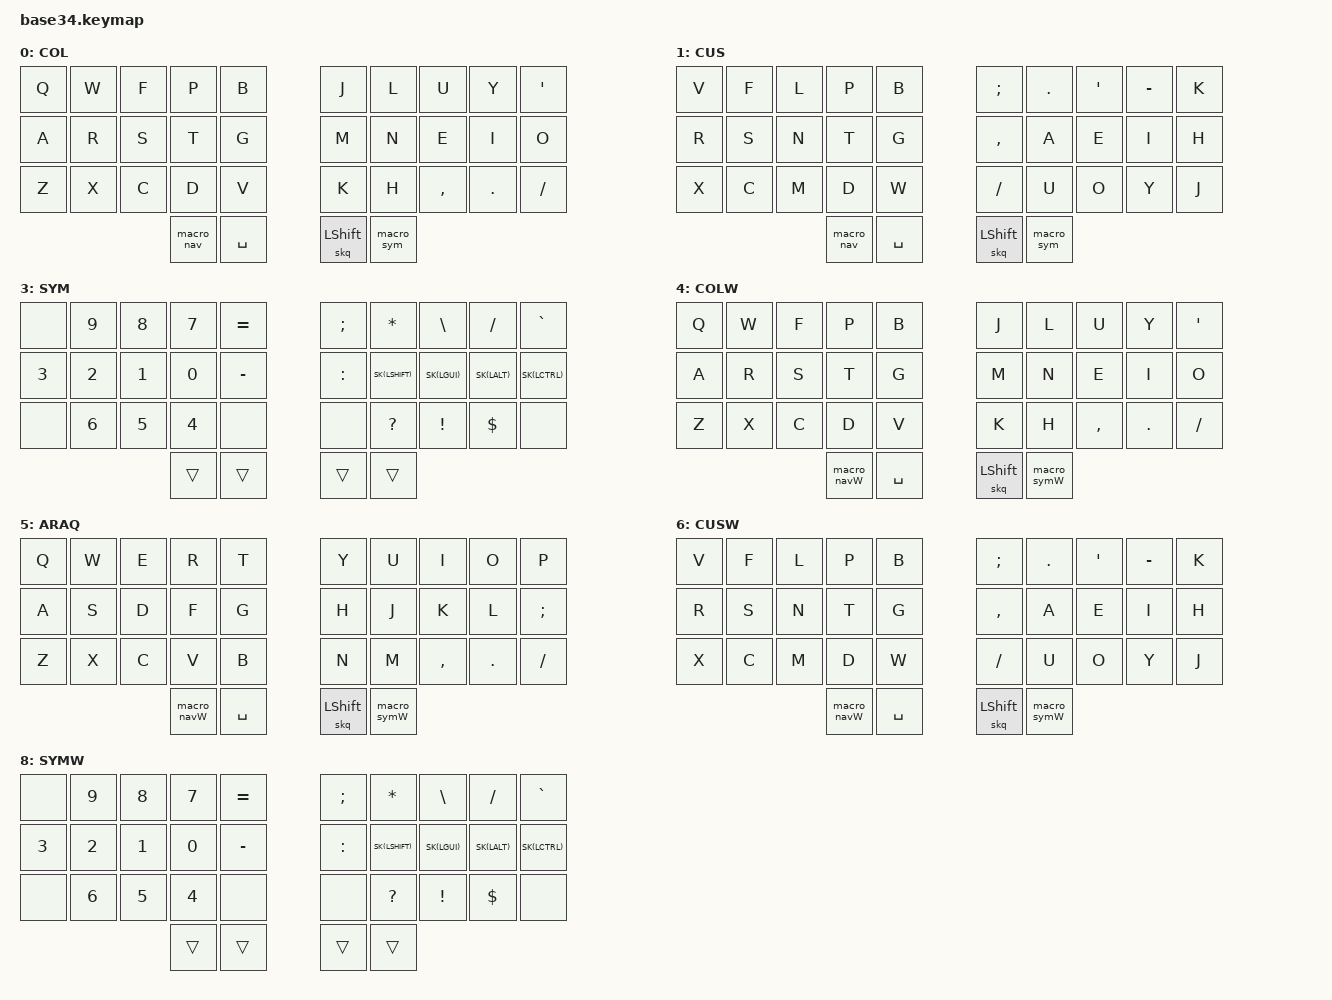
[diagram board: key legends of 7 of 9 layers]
/*
 * Copyright (c) 2020 The ZMK Contributors
 *
 * SPDX-License-Identifier: MIT
 */

#include <behaviors.dtsi>
#include <dt-bindings/zmk/keys.h>
#include <dt-bindings/zmk/bt.h>
#include <dt-bindings/zmk/outputs.h>

#define COL 0
#define CUS 1
#define NAV 2
#define SYM 3
#define COLW 4
#define ARAQ 5
#define CUSW 6
#define NAVW 7
#define SYMW 8

#define SK(KEY) &nk KEY KEY
// Keep sticky keys active for a long time so they effectively do not time out
#define STICKY_KEY_TIMEOUT 60000

&sk {
  release-after-ms = <STICKY_KEY_TIMEOUT>;
};

&caps_word {
  continue-list = <UNDERSCORE MINUS BACKSPACE>;
};

/* KEY POSITIONS
    ╭────────────────────╮ ╭────────────────────╮
    │  0   1   2   3   4 │ │  5   6   7   8   9 │
    │ 10  11  12  13  14 │ │ 15  16  17  18  19 │
    │ 20  21  22  23  24 │ │ 25  26  27  28  29 │
    ╰───────────╮ 30  31 │ │ 32  33 ╭───────────╯
                ╰────────╯ ╰────────╯
x f l p b  z u o y ' 
r s n t g  . a e i h 
v c m d w  / , q j k
*/

/ { 
  
                
  combos {
    #include "combos.dtsi"
  };
  
  macros {
    #include "macros.dtsi"
  };

  behaviors {
    // Sticky key on tap, normal key on hold
    // Useful for modifier-clicking without the modifier remaining active
     nk: not_so_sticky_key {
       compatible = "zmk,behavior-hold-tap";
       label = "NOT_SO_STICKY_KEY";
       #binding-cells = <2>;
       tapping_term_ms = <200>;
       flavor = "tap-preferred";
       bindings = <&kp>, <&sk>;
     };

    skq: sticky_key_quick_release {
      compatible = "zmk,behavior-sticky-key";
      label = "STICKY_KEY_QUICK_RELEASE";
      #binding-cells = <1>;
      bindings = <&kp>;
      quick-release;
      release-after-ms = <STICKY_KEY_TIMEOUT>;
    };


  };
 
        keymap {
                compatible = "zmk,keymap";
                      
        colemak {
            label = "COL";
            bindings = <
// ╭─────────────┬─────────────┬─────────────┬─────────────┬─────────────╮   ╭─────────────┬─────────────┬─────────────┬─────────────┬─────────────╮
     &kp Q         &kp W         &kp F         &kp P         &kp B             &kp J         &kp L         &kp U         &kp Y         &kp SQT
     &kp A         &kp R         &kp S         &kp T         &kp G             &kp M         &kp N         &kp E         &kp I         &kp O
     &kp Z         &kp X         &kp C         &kp D         &kp V             &kp K         &kp H         &kp COMMA     &kp DOT       &kp SLASH
// ╰─────────────┴─────────────┴─────────────┼─────────────┼─────────────┤   ├─────────────┼─────────────┼─────────────┴─────────────┴─────────────╯
                                               &macro_nav   &kp SPACE         &skq LSHIFT    &macro_sym
//                                           ╰─────────────┴─────────────╯   ╰─────────────┴─────────────╯
            >;
        };

        custom {
            label = "CUS";
            bindings = <
// ╭─────────────┬─────────────┬─────────────┬─────────────┬─────────────╮   ╭─────────────┬─────────────┬─────────────┬─────────────┬─────────────╮
     &kp V         &kp F         &kp L         &kp P         &kp B             &kp SEMI      &kp DOT       &kp SQT       &kp MINUS     &kp K
     &kp R         &kp S         &kp N         &kp T         &kp G             &kp COMMA     &kp A         &kp E         &kp I         &kp H
     &kp X         &kp C         &kp M         &kp D         &kp W             &kp SLASH     &kp U         &kp O         &kp Y         &kp J
// ╰─────────────┴─────────────┴─────────────┼─────────────┼─────────────┤   ├─────────────┼─────────────┼─────────────┴─────────────┴─────────────╯
                                               &macro_nav    &kp SPACE         &skq LSHIFT    &macro_sym
//                                           ╰─────────────┴─────────────╯   ╰─────────────┴─────────────╯
            >;
        };

        navitation {
            label = "NAV";
            bindings = <
// ╭─────────────┬─────────────┬─────────────┬─────────────┬─────────────╮   ╭─────────────┬─────────────┬─────────────┬─────────────┬─────────────╮
     &none         &kp ENTER     &kp BACKSPACE  &kp TAB       &kp DELETE        &kp LA(BACKSPACE) &none         &kp UP        &kp LG(Q)     &none
     SK(LCTRL)     SK(LALT)      SK(LGUI)       SK(LSHIFT)    &kp LG(A)         &kp LG(A)         &kp LEFT      &kp DOWN      &kp RIGHT     &kp LG(LC(LA(LS(P))))
     &none         &kp LG(X)     &kp LG(C)      &kp LG(V)     &none             &none             &kp ENTER     &kp BACKSPACE &kp TAB       &none
// ╰─────────────┴─────────────┴─────────────┼─────────────┼─────────────┤   ├─────────────┼─────────────┼─────────────┴─────────────┴─────────────╯
                                               &trans         &trans            &trans        &trans
//                                           ╰─────────────┴─────────────╯   ╰─────────────┴─────────────╯
            >;
        };
        symbols {
            label = "SYM";
            bindings = <
// ╭─────────────┬─────────────┬─────────────┬─────────────┬─────────────╮   ╭─────────────┬─────────────┬─────────────┬─────────────┬─────────────╮
     &none         &kp N9       &kp N8         &kp N7         &kp EQUAL         &kp SEMI      &kp ASTRK     &kp BSLH     &kp SLASH     &kp GRAVE
     &kp N3        &kp N2       &kp N1         &kp N0         &kp MINUS         &kp COLON     SK(LSHIFT)    SK(LGUI)     SK(LALT)      SK(LCTRL)
     &none         &kp N6       &kp N5         &kp N4         &none             &none         &kp QMARK     &kp EXCL     &kp DLLR      &none
// ╰─────────────┴─────────────┴─────────────┼─────────────┼─────────────┤   ├─────────────┼─────────────┼─────────────┴─────────────┴─────────────╯
                                               &trans         &trans            &trans       &trans
//                                           ╰─────────────┴─────────────╯   ╰─────────────┴─────────────╯
            >;
        };

        colemak_windows {
            label = "COLW";
            bindings = <
// ╭─────────────┬─────────────┬─────────────┬─────────────┬─────────────╮   ╭─────────────┬─────────────┬─────────────┬─────────────┬─────────────╮
     &kp Q         &kp W         &kp F         &kp P         &kp B             &kp J         &kp L         &kp U         &kp Y         &kp SQT
     &kp A         &kp R         &kp S         &kp T         &kp G             &kp M         &kp N         &kp E         &kp I         &kp O
     &kp Z         &kp X         &kp C         &kp D         &kp V             &kp K         &kp H         &kp COMMA     &kp DOT       &kp SLASH
// ╰─────────────┴─────────────┴─────────────┼─────────────┼─────────────┤   ├─────────────┼─────────────┼─────────────┴─────────────┴─────────────╯
                                               &macro_navW   &kp SPACE         &skq LSHIFT    &macro_symW
//                                           ╰─────────────┴─────────────╯   ╰─────────────┴─────────────╯
            >;
        };


        arabic_qwerty {
            label = "ARAQ";
            bindings = <
// ╭─────────────┬─────────────┬─────────────┬─────────────┬─────────────╮   ╭─────────────┬─────────────┬─────────────┬─────────────┬─────────────╮
     &kp Q         &kp W         &kp E         &kp R         &kp T             &kp Y         &kp U         &kp I         &kp O         &kp P
     &kp A         &kp S         &kp D         &kp F         &kp G             &kp H         &kp J         &kp K         &kp L         &kp SEMICOLON
     &kp Z         &kp X         &kp C         &kp V         &kp B             &kp N         &kp M         &kp COMMA     &kp DOT       &kp SLASH
// ╰─────────────┴─────────────┴─────────────┼─────────────┼─────────────┤   ├─────────────┼─────────────┼─────────────┴─────────────┴─────────────╯
                                               &macro_navW   &kp SPACE         &skq LSHIFT    &macro_symW
//                                           ╰─────────────┴─────────────╯   ╰─────────────┴─────────────╯
            >;
        };

          custom_windows {
            label = "CUSW";
            bindings = <
// ╭─────────────┬─────────────┬─────────────┬─────────────┬─────────────╮   ╭─────────────┬─────────────┬─────────────┬─────────────┬─────────────╮
     &kp V         &kp F         &kp L         &kp P         &kp B             &kp SEMI      &kp DOT       &kp SQT       &kp MINUS     &kp K
     &kp R         &kp S         &kp N         &kp T         &kp G             &kp COMMA     &kp A         &kp E         &kp I         &kp H
     &kp X         &kp C         &kp M         &kp D         &kp W             &kp SLASH     &kp U         &kp O         &kp Y         &kp J
// ╰─────────────┴─────────────┴─────────────┼─────────────┼─────────────┤   ├─────────────┼─────────────┼─────────────┴─────────────┴─────────────╯
                                               &macro_navW   &kp SPACE         &skq LSHIFT    &macro_symW
//                                           ╰─────────────┴─────────────╯   ╰─────────────┴─────────────╯
            >;
        };


        navigation_windows {
            label = "NAVW";
            bindings = <
// ╭─────────────┬─────────────┬─────────────┬─────────────┬─────────────╮   ╭─────────────┬─────────────┬─────────────┬─────────────┬─────────────╮
     &none         &kp ENTER     &kp BACKSPACE  &kp TAB      &kp DELETE        &kp LC(BACKSPACE)  &none         &kp UP        &kp LA(F4)    &none
     SK(LGUI)      SK(LALT)      SK(LCTRL)      SK(LSHIFT)   &kp LC(A)         &kp LC(A)          &kp LEFT      &kp DOWN      &kp RIGHT     &kp LC(LA(LS(P)))
     &none         &kp LC(X)     &kp LC(C)      &kp LC(V)    &none             &none              &kp ENTER     &kp BACKSPACE &kp TAB       &none
// ╰─────────────┴─────────────┴─────────────┼─────────────┼─────────────┤   ├─────────────┼─────────────┼─────────────┴─────────────┴─────────────╯
                                               &trans          &trans            &trans        &trans
//                                           ╰─────────────┴─────────────╯   ╰─────────────┴─────────────╯
            >;
        };

        symbols_windows {
            label = "SYMW";
            bindings = <
// ╭─────────────┬─────────────┬─────────────┬─────────────┬─────────────╮   ╭─────────────┬─────────────┬─────────────┬─────────────┬─────────────╮
     &none         &kp N9       &kp N8         &kp N7         &kp EQUAL         &kp SEMI      &kp ASTRK     &kp BSLH     &kp SLASH     &kp GRAVE
     &kp N3        &kp N2       &kp N1         &kp N0         &kp MINUS         &kp COLON     SK(LSHIFT)    SK(LGUI)     SK(LALT)      SK(LCTRL)
     &none         &kp N6       &kp N5         &kp N4         &none             &none         &kp QMARK     &kp EXCL     &kp DLLR      &none
// ╰─────────────┴─────────────┴─────────────┼─────────────┼─────────────┤   ├─────────────┼─────────────┼─────────────┴─────────────┴─────────────╯
                                               &trans        &trans            &trans        &trans
//                                           ╰─────────────┴─────────────╯   ╰─────────────┴─────────────╯
            >;
        };
};

};
